# NUC1263AE register map
File version: 1.0
Registers are 32-bit, read-write, reset 0x0 unless marked. A register's access mark holds for its fields unless they carry their own. Offsets are from the block's base; [hi:lo] are bit positions; {n}, {i} and the like mark numbered series.

## SYS — SYS Register Map
Base 0x50000000
0x00 SYS_PDID ro reset not defined — Part Device Identification Number Register
  [31:0] PDID — Part Device Identification Number (Read Only). This register reflects device part number code. Software can read this register to identify which device is used.
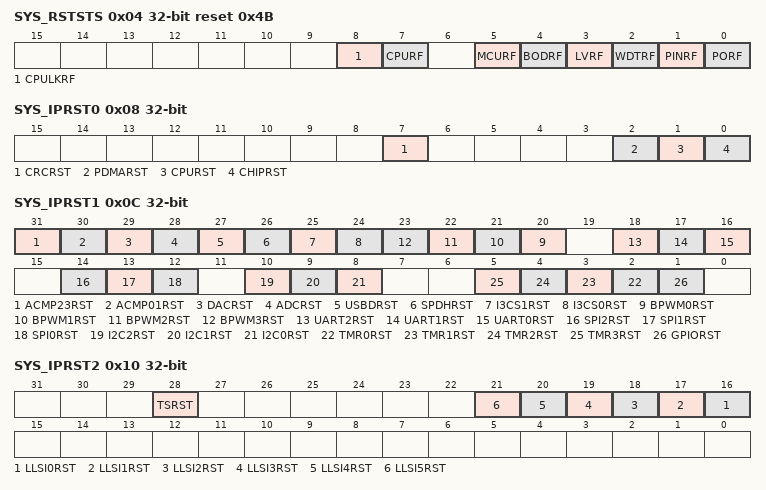
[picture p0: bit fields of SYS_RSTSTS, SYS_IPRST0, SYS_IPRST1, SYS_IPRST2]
0x04 SYS_RSTSTS reset 0x4B — System Reset Status Register
  [8] CPULKRF — CPU Lockup Reset Flag. The CPU lockup reset flag is set by hardware If Cortex-M23 lockup happened. Note 1: This bit can be cleared by software writing 1. Note 2: When CPU lockup happened under ICE is connected, This flag will set to 1 but chip will not reset.
    0=No reset from CPU lockup happened; 1=The Cortex-M23 lockup happened and chip is reset
  [7] CPURF — CPU Reset Flag. The CPU reset flag is set by hardware if software writes CPURST (SYS_IPRST0[1]) 1 to reset Cortex-M23 Core and Flash Memory Controller (FMC). Note: This bit can be cleared by software writing 1.
    0=No reset from CPU; 1=The Cortex-M23 Core and FMC are reset by software setting CPURST to 1
  [5] MCURF — MCU Reset Flag. The MCU reset flag is set by the 'Reset Signal' from the Cortex-M23 Core to indicate the previous reset source. Note: This bit can be cleared by software writing 1.
    0=No reset from Cortex-M23; 1=The Cortex-M23 had issued the reset signal to reset the system by writing 1 to the bit SYSRESETREQ(AIRCR[2], Application Interrupt and Reset Control Register, address = 0xE000ED0C) in system control registers of Cortex-M23 core
  [4] BODRF — BOD Reset Flag. The BOD reset flag is set by the 'Reset Signal' from the Brown-out Detector to indicate the previous reset source. Note: This bit can be cleared by software writing 1.
    0=No reset from BOD; 1=The BOD had issued the reset signal to reset the system
  [3] LVRF — LVR Reset Flag. The LVR reset flag is set by the 'Reset Signal' from the Low Voltage Reset Controller to indicate the previous reset source. Note: This bit can be cleared by software writing 1.
    0=No reset from LVR; 1=LVR controller had issued the reset signal to reset the system
  [2] WDTRF — WDT Reset Flag. The WDT reset flag is set by the 'Reset Signal' from the Watchdog Timer or Window Watchdog Timer to indicate the previous reset source. Note 1: This bit can be cleared by software writing 1. Note 2: Watchdog Timer register RSTF(WDT_CTL[2]) bit is set if the system has been reset by WDT time-out reset. Window Watchdog Timer register WWDTRF(WWDT_STATUS[1]) bit is set if the system has been reset by WWDT time-out reset.
    0=No reset from watchdog timer or window watchdog timer; 1=The watchdog timer or window watchdog timer had issued the reset signal to reset the system
  [1] PINRF — nRESET Pin Reset Flag. The nRESET pin reset flag is set by the 'Reset Signal' from the nRESET Pin to indicate the previous reset source. Note: This bit can be cleared by software writing 1.
    0=No reset from nRESET pin; 1=Pin nRESET had issued the reset signal to reset the system
  [0] PORF — POR Reset Flag. The POR reset flag is set by the 'Reset Signal' from the Power-on Reset (POR) Controller or bit CHIPRST (SYS_IPRST0[0]) to indicate the previous reset source. Note: This bit can be cleared by software writing 1.
    0=No reset from POR or CHIPRST; 1=Power-on Reset (POR) or CHIPRST had issued the reset signal to reset the system
0x08 SYS_IPRST0 — Peripheral Reset Control Register 0
  [7] CRCRST — CRC Calculation Controller Reset (Write Protect). Set this bit to 1 will generate a reset signal to the CRC calculation controller. User needs to set this bit to 0 to release from the reset state. Note: This bit is write protected. Refer to the SYS_REGLCTL register.
    0=CRC calculation controller normal operation; 1=CRC calculation controller reset
  [2] PDMARST — PDMA Controller Reset (Write Protect). Setting this bit to 1 will generate a reset signal to the PDMA. User needs to set this bit to 0 to release from reset state. Note: This bit is write protected. Refer to the SYS_REGLCTL register.
    0=PDMA controller normal operation; 1=PDMA controller reset
  [1] CPURST — Processor Core One-shot Reset (Write Protect). Setting this bit will only reset the processor core and Flash Memory Controller (FMC), and this bit will automatically return to 0 after the 2 clock cycles. Note: This bit is write protected. Refer to the SYS_REGLCTL register.
    0=Processor core normal operation; 1=Processor core one-shot reset
  [0] CHIPRST — Chip One-shot Reset (Write Protect). Setting this bit will reset the whole chip, including Processor core and all peripherals, and this bit will automatically return to 0 after the 2 clock cycles. The CHIPRST is same as the POR reset, all the chip controllers is reset and the chip setting from Flash are also reload. About the difference between CHIPRST and SYSRESETREQ(AIRCR[2]), please refer to section 6.2.2. Note: This bit is write protected. Refer to the SYS_REGLCTL register.
    0=Chip normal operation; 1=Chip one-shot reset
0x0C SYS_IPRST1 — Peripheral Reset Control Register 1
  [31] ACMP23RST — ACMP23 Controller Reset
    0=ACMP23 controller normal operation; 1=ACMP23 controller reset
  [30] ACMP01RST — ACMP01 Controller Reset
    0=ACMP01 controller normal operation; 1=ACMP01 controller reset
  [29] DACRST — DAC Controller Reset
    0=DAC controller normal operation; 1=DAC controller reset
  [28] ADCRST — ADC Controller Reset
    0=ADC controller normal operation; 1=ADC controller reset
  [27] USBDRST — USB Device Controller Reset
    0=USB device controller normal operation; 1=USB device controller reset
  [26] SPDHRST — SPD5 Hub Controller Reset
    0=SPD5 Hub controller normal operation; 1=SPD5 Hub controller reset
  [25] I3CS1RST — I3CS1 Controller Reset
    0=I3CS1 controller normal operation; 1=I3CS1 controller reset
  [24] I3CS0RST — I3CS0 Controller Reset
    0=I3CS0 controller normal operation; 1=I3CS0 controller reset
  [n+20] BPWM{n}RST (n=0..3) — BPWM{n} Controller Reset
    0=BPWM{n} controller normal operation; 1=BPWM{n} controller reset
  [18] UART2RST — UART2 Controller Reset
    0=UART2 controller normal operation; 1=UART2 controller reset
  [17] UART1RST — UART1 Controller Reset
    0=UART1 controller normal operation; 1=UART1 controller reset
  [16] UART0RST — UART0 Controller Reset
    0=UART0 controller normal operation; 1=UART0 controller reset
  [14] SPI2RST — SPI2 Controller Reset
    0=SPI2 controller normal operation; 1=SPI2 controller reset
  [13] SPI1RST — SPI1 Controller Reset
    0=SPI1 controller normal operation; 1=SPI1 controller reset
  [12] SPI0RST — SPI0 Controller Reset
    0=SPI0 controller normal operation; 1=SPI0 controller reset
  [10] I2C2RST — I2C2 Controller Reset
    0=I2C2 controller normal operation; 1=I2C2 controller reset
  [9] I2C1RST — I2C1 Controller Reset
    0=I2C1 controller normal operation; 1=I2C1 controller reset
  [8] I2C0RST — I2C0 Controller Reset
    0=I2C0 controller normal operation; 1=I2C0 controller reset
  [n+2] TMR{n}RST (n=0..3) — Timer{n} Controller Reset
    0=Timer{n} controller normal operation; 1=Timer{n} controller reset
  [1] GPIORST — GPIO Controller Reset
    0=GPIO controller normal operation; 1=GPIO controller reset
0x10 SYS_IPRST2 — Peripheral Reset Control Register 2
  [28] TSRST — TS Controller Reset
    0=Temperature Sensor controller normal operation; 1=Temperature Sensor controller reset
  [n+16] LLSI{n}RST (n=0..5) — LLSI{n} Controller Reset
    0=LED Lighting Strip Interface {n} controller normal operation; 1=LED Lighting Strip Interface {n} controller reset
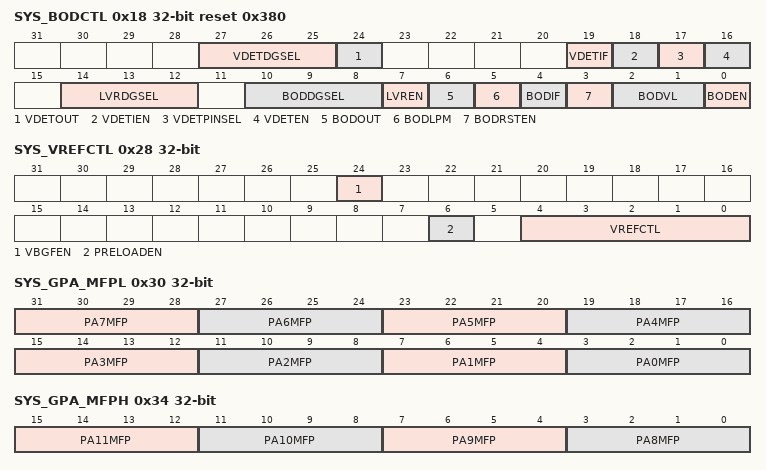
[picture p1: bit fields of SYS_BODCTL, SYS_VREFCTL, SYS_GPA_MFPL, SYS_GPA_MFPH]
0x18 SYS_BODCTL reset 0x380 (reset mask 0xFFFFFFF0) — Brown-out Detector Control Register
  [27:25] VDETDGSEL — Voltage Detector Output De-glitch Time Select (Write Protect). Note: These bits are write protected. Refer to the SYS_REGLCTL register.
    0=VDET output is sampled by VDET clock; 1=16 system clock (HCLK); 2=32 system clock (HCLK); 3=64 system clock (HCLK); 4=128 system clock (HCLK); 5=256 system clock (HCLK); 6=512 system clock (HCLK); 7=1024 system clock (HCLK)
  [24] VDETOUT — Voltage Detector Output Status. It means the detected voltage is lower than Band-gap. If the VDETEN is 0, VDET function is disabled. This bit always responds 0.
    0=VDET output status is 0; 1=VDET output status is 1
  [19] VDETIF — Voltage Detector Interrupt Flag. Note: This bit can be cleared by software writing 1.
    0=VDET does not detect any voltage draft at external pin down through or up through the voltage of Band-gap; 1=When VDET detects the external pin is dropped down through the voltage of Band-gap or the external pin is raised up through the voltage of Band-gap, this bit is set to 1 and the voltage detector interrupt is requested if voltage detector interrupt is enabled
  [18] VDETIEN — Voltage Detector Interrupt Enable Bit
    0=VDET interrupt Disabled; 1=VDET interrupt Enabled
  [17] VDETPINSEL — Voltage Detector External Input Voltage Pin Selection. Note 1: If VDET_P0 is selected, multi-function pin must be selected correctly in PB0MFP (SYS_GPB_MFPL[3:0]). Note 2: If VDET_P1 is selected, multi-function pin must be selected correctly in PB1MFP (SYS_GPB_MFPL[7:4]).
    0=The input voltage is from VDET_P0 (PB.0); 1=The input voltage is from VDET_P1 (PB.1)
  [16] VDETEN — Voltage Detector Enable Bit. Note 1: This function is still active in whole chip Power-down mode. Note 2: This function need use LIRC or LXT as VDET clock source, which is selected in VDETCKSEL (CLK_BODCLK[0]). Note 2: The input pin for VDET detect voltage is selectable by VDETPINSEL (SYS_BODCTL[17]).
    0=VDET detect external input voltage function Disabled; 1=VDET detect external input voltage function Enabled
  [14:12] LVRDGSEL — LVR Output De-glitch Time Select (Write Protect). Note: These bits are write protected. Refer to the SYS_REGLCTL register.
    0=Without de-glitch function; 1=4 system clock (HCLK); 2=8 system clock (HCLK); 3=16 system clock (HCLK); 4=32 system clock (HCLK); 5=64 system clock (HCLK); 6=128 system clock (HCLK); 7=256 system clock (HCLK)
  [10:8] BODDGSEL — Brown-out Detector Output De-glitch Time Select (Write Protect). Note: These bits are write protected. Refer to the SYS_REGLCTL register.
    0=BOD output is sampled by RC10K clock; 1=4 system clock (HCLK); 2=8 system clock (HCLK); 3=16 system clock (HCLK); 4=32 system clock (HCLK); 5=64 system clock (HCLK); 6=128 system clock (HCLK); 7=256 system clock (HCLK)
  [7] LVREN — Low Voltage Reset Enable Bit (Write Protect). The LVR function resets the chip when the input power voltage is lower than LVR circuit setting. LVR function is enabled by default. Note 1: After enabling the bit, the LVR function will be active with 200us delay for LVR output stable (default). Note 2: This bit is write protected. Refer to the SYS_REGLCTL register.
    0=Low Voltage Reset function Disabled; 1=Low Voltage Reset function Enabled
  [6] BODOUT — Brown-out Detector Output Status. It means the detected voltage is lower than BODVL setting. If the BODEN is 0, BOD function is disabled. This bit always responds 0.
    0=Brown-out Detector output status is 0; 1=Brown-out Detector output status is 1
  [5] BODLPM — Brown-out Detector Low Power Mode (Write Protect). Note 1: The BOD consumes about 100uA in normal mode, the low power mode can reduce the current to about 1/10 but slow the BOD response. Note 2: This bit is write protected. Refer to the SYS_REGLCTL register.
    0=BOD operated in normal mode (default); 1=BOD Low Power mode Enabled
  [4] BODIF — Brown-out Detector Interrupt Flag. Note: This bit can be cleared by software writing 1.
    0=Brown-out Detector does not detect any voltage draft at AVDD down through or up through the voltage of BODVL setting; 1=When Brown-out Detector detects the AVDD is dropped down through the voltage of BODVL setting or the AVDD is raised up through the voltage of BODVL setting, this bit is set to 1 and the brown-out interrupt is requested if brown-out interrupt is enabled
  [3] BODRSTEN — Brown-out Reset Enable Bit (Write Protect). The default value is set by Flash controller user configuration register CBORST(CONFIG0[20]) bit. Note 1: While the Brown-out Detector function is enabled (BODEN high) and BOD reset function is enabled (BODRSTEN high), BOD will assert a signal to reset chip when the detected voltage is lower than the threshold (BODOUT high). While the BOD function is enabled (BODEN high) and BOD interrupt function is enabled (BODRSTEN low), BOD will assert an interrupt if BODOUT is high. BOD interrupt will keep till to the BODEN set to 0. BOD interrupt can be blocked by disabling the NVIC BOD interrupt or disabling BOD function (set BODEN low). Note 2: This bit is write protected. Refer to the SYS_REGLCTL register.
    0=Brown-out 'INTERRUPT' function Enabled; 1=Brown-out 'RESET' function Enabled
  [2:1] BODVL — Brown-out Detector Threshold Voltage Selection (Write Protect). The default value is set by Flash controller user configuration register CBOV (CONFIG0 [22:21]). Note: These bits are write protected. Refer to the SYS_REGLCTL register.
    0=Brown-Out Detector threshold voltage is 2.2V; 1=Brown-Out Detector threshold voltage is 2.7V; 2=Brown-Out Detector threshold voltage is 3.7V; 3=Brown-Out Detector threshold voltage is 4.5V
  [0] BODEN — Brown-out Detector Enable Bit (Write Protect). The default value is set by Flash controller user configuration register CBODEN (CONFIG0 [23]). Note: This bit is write protected. Refer to the SYS_REGLCTL register.
    0=Brown-out Detector function Disabled; 1=Brown-out Detector function Enabled
0x1C SYS_IVSCTL — Internal Voltage Source Control Register
  [1] VBGUGEN — Band-gap VBG Unity Gain Buffer Enable Bit. This bit is used to enable/disable Band-gap VBG unity gain buffer function. Note: After this bit is set to 1, the value of VBG unity gain buffer output voltage can be obtained from ADC conversion result. Please refer to ADC function chapter for details.
    0=VBG unity gain buffer function Disabled (default); 1=VBG unity gain buffer function Enabled
0x24 SYS_PORCTL — Power-on Reset Controller Register
  [15:0] POROFF — Power-on Reset Enable Bit (Write Protect). When powered on, the POR circuit generates a reset signal to reset the whole chip function, but noise on the power may cause the POR active again. User can disable internal POR circuit to avoid unpredictable noise to cause chip reset by writing 0x5AA5 to this field. The POR function will be active again when this field is set to another value or chip is reset by other reset source, including: nRESET, Watchdog, LVR reset, BOD reset, ICE reset command and the software-chip reset function. Note: These bits are write protected. Refer to the SYS_REGLCTL register.
0x28 SYS_VREFCTL — VREF Control Register
  [24] VBGFEN — Chip Internal Voltage Band-gap Force Enable Bit (Write Protect)
    0=Chip internal voltage band-gap controlled by ADC/ACMP if source selected; 1=Chip internal voltage band-gap force enable
  [6] PRELOADEN — Pre-load Function Enable Bit (Write Protect). This bit should be enabled and keep during Tstable when VREFCTL(SYS_VREFCTL[4:0]) change setting(except set to 00000). Tstable depends on different situations has different requirement, please refer to Datasheet. Note : This bit is write protected. Refer to the SYS_REGLCTL register.
    0=VREF Pre-load function Disabled. (Default); 1=VREF Pre-load function Enabled
  [4:0] VREFCTL — VREF Control Bits (Write Protect). Note: These bits are write protected. Refer to the SYS_REGLCTL register.
    0=VREF is from external pin; 2=VREF is from internal reference voltage 2.048V; 6=VREF is from internal reference voltage 2.56V; 10=VREF is from internal reference voltage 3.072V; 14=VREF is from internal reference voltage 4.096V
0x30 SYS_GPA_MFPL — GPIOA Low Byte Multiple Function Control Register
  [31:28] PA7MFP — PA.7 Multi-function Pin Selection
    2=SPI1_CLK; 7=UART0_TXD; 8=I2C1_SCL; 11=BPWM3_CH4; 12=BPWM1_CH2; 13=ACMP0_WLAT; 14=TM2; 15=INT1
  [27:24] PA6MFP — PA.6 Multi-function Pin Selection
    2=SPI1_SS; 7=UART0_RXD; 8=I2C1_SDA; 11=BPWM3_CH5; 12=BPWM1_CH3; 13=ACMP1_WLAT; 14=TM3; 15=INT0
  [23:20] PA5MFP — PA.5 Multi-function Pin Selection
    2=SPI1_I2SMCLK; 4=SPI0_I2SMCLK; 5=SPI2_I2SMCLK; 6=I3CS0_SCL; 7=UART0_nCTS; 8=UART0_TXD; 9=I2C0_SCL; 12=BPWM0_CH5; 13=BPWM2_CH0; 15=DAC2_ST
  [19:16] PA4MFP — PA.4 Multi-function Pin Selection
    4=SPI0_I2SMCLK; 6=I3CS0_SDA; 7=UART0_nRTS; 8=UART0_RXD; 9=I2C0_SDA; 12=BPWM0_CH4; 13=BPWM2_CH1; 15=DAC3_ST
  [15:12] PA3MFP — PA.3 Multi-function Pin Selection
    2=SPI_SS_MUX; 4=SPI0_SS; 5=SPI2_SS; 6=I3CS1_SCL; 7=I2C0_SMBAL; 8=UART1_TXD; 9=I2C1_SCL; 10=LLSI4_OUT; 12=BPWM0_CH3; 13=BPWM2_CH2; 14=CLKO; 15=ACMP2_WLAT
  [11:8] PA2MFP — PA.2 Multi-function Pin Selection
    2=SPI_CLK_MUX; 4=SPI0_CLK; 5=SPI2_CLK; 6=I3CS1_SDA; 7=I2C0_SMBSUS; 8=UART1_RXD; 9=I2C1_SDA; 10=LLSI5_OUT; 12=BPWM0_CH2; 13=BPWM2_CH3; 15=ACMP3_WLAT
  [7:4] PA1MFP — PA.1 Multi-function Pin Selection
    2=SPI_MISO_MUX; 4=SPI0_MISO; 5=SPI2_MISO; 6=I3CS0_SCL; 7=UART0_TXD; 8=UART1_nCTS; 9=I2C2_SCL; 12=BPWM0_CH1; 13=BPWM2_CH4; 15=ACMP2_O
  [3:0] PA0MFP — PA.0 Multi-function Pin Selection
    2=SPI_MOSI_MUX; 4=SPI0_MOSI; 5=SPI2_MOSI; 6=I3CS0_SDA; 7=UART0_RXD; 8=UART1_nRTS; 9=I2C2_SDA; 12=BPWM0_CH0; 13=BPWM2_CH5; 14=ACMP3_O; 15=DAC0_ST
0x34 SYS_GPA_MFPH — GPIOA High Byte Multiple Function Control Register
  [15:12] PA11MFP — PA.11 Multi-function Pin Selection
    3=SPI1_MOSI; 4=SPI2_SS; 7=I2C2_SCL; 9=BPWM0_CH0; 13=TM0_EXT; 14=DAC1_ST
  [11:8] PA10MFP — PA.10 Multi-function Pin Selection
    3=SPI1_MISO; 4=SPI2_CLK; 7=I2C2_SDA; 9=BPWM0_CH1; 10=I2C1_SCL; 13=TM1_EXT; 14=DAC0_ST
  [7:4] PA9MFP — PA.9 Multi-function Pin Selection
    3=SPI1_CLK; 4=SPI2_MISO; 7=UART1_TXD; 9=BPWM0_CH2; 10=I2C1_SDA; 13=TM2_EXT; 14=DAC2_ST
  [3:0] PA8MFP — PA.8 Multi-function Pin Selection
    3=SPI1_SS; 4=SPI2_MOSI; 7=UART1_RXD; 9=BPWM0_CH3; 10=I2C0_SCL; 13=TM3_EXT; 14=DAC3_ST; 15=INT4
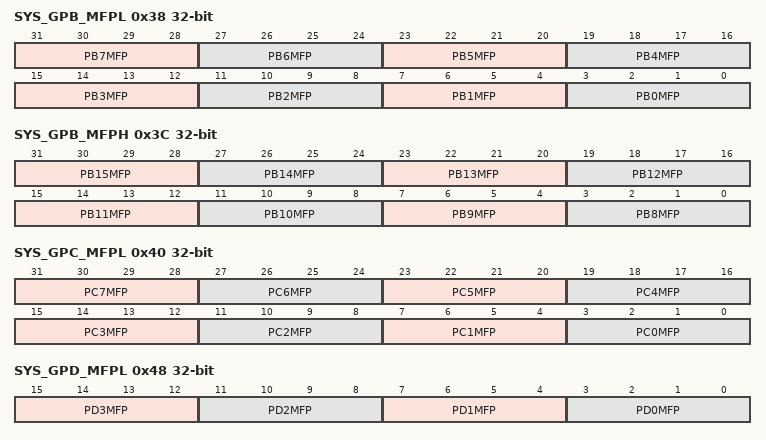
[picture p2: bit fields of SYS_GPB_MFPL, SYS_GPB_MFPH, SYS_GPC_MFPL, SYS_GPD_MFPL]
0x38 SYS_GPB_MFPL — GPIOB Low Byte Multiple Function Control Register
  [31:28] PB7MFP — PB.7 Multi-function Pin Selection
    1=ADC0_CH7, ACMP3_N; 6=UART1_TXD; 10=BPWM1_CH4; 12=BPWM3_CH4; 13=INT5; 15=ACMP0_O
  [27:24] PB6MFP — PB.6 Multi-function Pin Selection
    1=ADC0_CH6, ACMP2_N, ACMP3_P1; 6=UART1_RXD; 10=BPWM1_CH5; 12=BPWM3_CH5; 13=INT4; 15=ACMP1_O
  [23:20] PB5MFP — PB.5 Multi-function Pin Selection
    1=ADC0_CH5, ACMP1_N, ACMP2_P1, ACMP3_P0; 2=SPI1_MISO; 6=I2C0_SCL; 11=BPWM2_CH0; 12=LLSI4_OUT; 13=UART2_TXD; 14=TM0; 15=INT0
  [19:16] PB4MFP — PB.4 Multi-function Pin Selection
    1=ADC0_CH4, ACMP0_N, ACMP1_P1, ACMP2_P0; 2=SPI1_MOSI; 6=I2C0_SDA; 11=BPWM2_CH1; 12=LLSI5_OUT; 13=UART2_RXD; 14=TM1; 15=INT1
  [15:12] PB3MFP — PB.3 Multi-function Pin Selection
    1=ADC0_CH3, ACMP0_P1, ACMP1_P0; 2=SPI1_CLK; 4=I2C1_SCL; 6=UART1_TXD; 7=I2C2_SCL; 11=BPWM2_CH2; 14=TM2; 15=INT2
  [11:8] PB2MFP — PB.2 Multi-function Pin Selection
    1=ADC0_CH2, ACMP0_P0; 2=SPI1_SS; 4=I2C1_SDA; 6=UART1_RXD; 7=I2C2_SDA; 8=SPI0_I2SMCLK; 11=BPWM2_CH3; 14=TM3; 15=INT3
  [7:4] PB1MFP — PB.1 Multi-function Pin Selection
    1=ADC0_CH1, VDET_P1, SPDH_HSA; 2=SPI1_I2SMCLK; 7=UART2_TXD; 9=I2C1_SCL; 11=BPWM2_CH4; 12=BPWM3_CH4; 13=TM3_EXT
  [3:0] PB0MFP — PB.0 Multi-function Pin Selection
    1=ADC0_CH0, VDET_P0; 3=SPI0_SS; 4=SPI2_I2SMCLK; 7=UART2_RXD; 8=SPI0_I2SMCLK; 9=I2C1_SDA; 11=BPWM2_CH5; 12=BPWM3_CH5
0x3C SYS_GPB_MFPH — GPIOB High Byte Multiple Function Control Register
  [31:28] PB15MFP — PB.15 Multi-function Pin Selection
    1=ADC0_CH15, DAC3_OUT, ACMP2_P3, ACMP3_P3; 4=SPI0_SS; 6=UART0_nCTS; 8=I2C2_SMBAL; 10=LLSI0_OUT; 11=BPWM3_CH0; 13=TM0_EXT
  [27:24] PB14MFP — PB.14 Multi-function Pin Selection
    1=ADC0_CH14, DAC2_OUT, ACMP2_P2, ACMP3_P2; 4=SPI0_CLK; 6=UART0_nRTS; 8=I2C2_SMBSUS; 10=LLSI1_OUT; 11=BPWM3_CH1; 13=TM1_EXT; 14=CLKO
  [23:20] PB13MFP — PB.13 Multi-function Pin Selection
    1=ADC0_CH13, DAC1_OUT, ACMP0_P3, ACMP1_P3; 4=SPI0_MISO; 6=UART0_TXD; 8=I2C2_SCL; 10=LLSI2_OUT; 11=BPWM3_CH2; 13=TM2_EXT
  [19:16] PB12MFP — PB.12 Multi-function Pin Selection
    1=ADC0_CH12, DAC0_OUT, ACMP0_P2, ACMP1_P2; 4=SPI0_MOSI; 6=UART0_RXD; 8=I2C2_SDA; 10=LLSI3_OUT; 11=BPWM3_CH3; 13=TM3_EXT
  [15:12] PB11MFP — PB.11 Multi-function Pin Selection
    1=ADC0_CH11; 5=UART0_nCTS; 7=I2C1_SCL; 9=SPI0_I2SMCLK; 10=BPWM1_CH0
  [11:8] PB10MFP — PB.10 Multi-function Pin Selection
    1=ADC0_CH10; 5=UART0_nRTS; 7=I2C1_SDA; 10=BPWM1_CH1
  [7:4] PB9MFP — PB.9 Multi-function Pin Selection
    1=ADC0_CH9; 5=UART0_TXD; 6=UART1_nCTS; 7=I2C1_SMBAL; 9=I2C0_SCL; 10=BPWM1_CH2
  [3:0] PB8MFP — PB.8 Multi-function Pin Selection
    1=ADC0_CH8; 5=UART0_RXD; 6=UART1_nRTS; 7=I2C1_SMBSUS; 9=I2C0_SDA; 10=BPWM1_CH3
0x40 SYS_GPC_MFPL — GPIOC Low Byte Multiple Function Control Register
  [31:28] PC7MFP — PC.7 Multi-function Pin Selection
    4=SPI1_MISO; 7=UART0_nCTS; 8=I2C1_SMBAL; 11=BPWM3_CH2; 12=BPWM1_CH0; 14=TM0; 15=INT3
  [27:24] PC6MFP — PC.6 Multi-function Pin Selection
    4=SPI1_MOSI; 7=UART0_nRTS; 8=I2C1_SMBSUS; 11=BPWM3_CH3; 12=BPWM1_CH1; 14=TM1; 15=INT2
  [23:20] PC5MFP — PC.5 Multi-function Pin Selection
    8=UART2_TXD; 9=I2C1_SCL; 12=BPWM3_CH0; 15=LLSI0_OUT
  [19:16] PC4MFP — PC.4 Multi-function Pin Selection
    2=SPI1_I2SMCLK; 8=UART2_RXD; 9=I2C1_SDA; 12=BPWM3_CH1; 15=LLSI1_OUT
  [15:12] PC3MFP — PC.3 Multi-function Pin Selection
    2=SPI1_MISO; 7=I2C2_SMBAL; 8=UART2_nRTS; 9=I2C0_SMBAL; 10=I2C0_SCL; 12=BPWM3_CH2; 15=LLSI2_OUT
  [11:8] PC2MFP — PC.2 Multi-function Pin Selection
    2=SPI1_MOSI; 7=I2C2_SMBSUS; 8=UART2_nCTS; 9=I2C0_SMBSUS; 10=I2C0_SDA; 12=BPWM3_CH3; 15=LLSI3_OUT
  [7:4] PC1MFP — PC.1 Multi-function Pin Selection
    2=SPI1_CLK; 7=I2C1_SCL; 8=UART2_TXD; 9=I2C0_SCL; 11=ADC0_ST; 12=BPWM3_CH4; 13=BPWM2_CH1; 14=ACMP0_O
  [3:0] PC0MFP — PC.0 Multi-function Pin Selection
    2=SPI1_SS; 7=I2C1_SDA; 8=UART2_RXD; 9=I2C0_SDA; 12=BPWM3_CH5; 13=BPWM3_CH3; 14=ACMP1_O
0x44 SYS_GPC_MFPH — GPIOC High Byte Multiple Function Control Register
  [27:24] PC14MFP — PC14 Multi-function Pin Selection
    2=SPI1_MOSI; 4=SPI0_I2SMCLK; 13=TM1; 15=DAC1_ST
0x48 SYS_GPD_MFPL — GPIOD Low Byte Multiple Function Control Register
  [15:12] PD3MFP — PD.3 Multi-function Pin Selection
    4=SPI0_SS; 9=UART0_TXD
  [11:8] PD2MFP — PD.2 Multi-function Pin Selection
    4=SPI0_CLK; 9=UART0_RXD
  [7:4] PD1MFP — PD.1 Multi-function Pin Selection
    4=SPI0_MISO
  [3:0] PD0MFP — PD.0 Multi-function Pin Selection
    4=SPI0_MOSI; 14=TM2
0x4C SYS_GPD_MFPH — GPIOD High Byte Multiple Function Control Register
  [31:28] PD15MFP — PD.15 Multi-function Pin Selection
    12=BPWM2_CH5; 14=TM3; 15=INT1
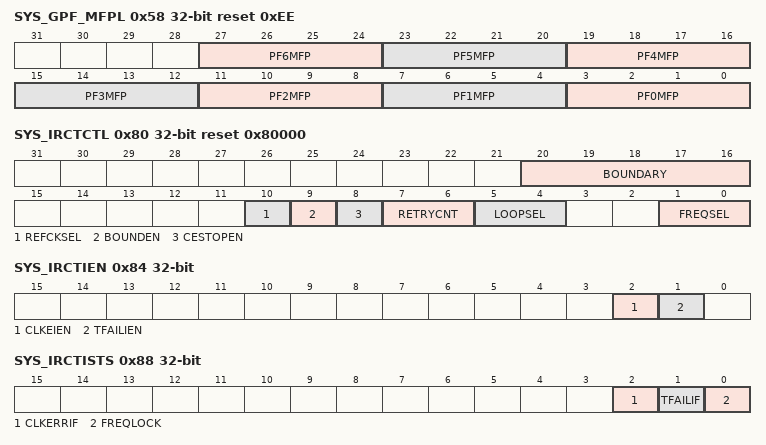
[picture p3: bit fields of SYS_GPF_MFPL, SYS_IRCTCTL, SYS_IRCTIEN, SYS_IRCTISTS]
0x58 SYS_GPF_MFPL reset 0xEE — GPIOF Low Byte Multiple Function Control Register
  [27:24] PF6MFP — PF.6 Multi-function Pin Selection
    5=SPI0_MOSI; 10=I2C0_SDA; 11=LLSI3_OUT; 12=BPWM2_CH4; 13=CLKO; 14=TM3; 15=INT5
  [23:20] PF5MFP — PF.5 Multi-function Pin Selection
    2=UART2_RXD; 3=SPI1_SS; 4=UART2_nCTS; 5=SPI0_CLK; 7=BPWM2_CH0; 8=BPWM0_CH4; 9=I2C0_SCL; 10=X32_IN; 11=ADC0_ST; 13=ACMP2_WLAT
  [19:16] PF4MFP — PF.4 Multi-function Pin Selection
    2=UART2_TXD; 4=UART2_nRTS; 5=SPI0_MISO; 7=BPWM2_CH1; 8=BPWM0_CH5; 9=I2C0_SDA; 10=X32_OUT; 11=BPWM2_CH5; 12=BPWM3_CH5; 13=ACMP3_WLAT
  [15:12] PF3MFP — PF.3 Multi-function Pin Selection
    3=UART0_TXD; 4=I2C0_SCL; 7=UART2_RXD; 9=BPWM0_CH3; 10=XT1_IN; 11=BPWM1_CH0; 13=ACMP2_O
  [11:8] PF2MFP — PF.2 Multi-function Pin Selection
    3=UART0_RXD; 4=I2C0_SDA; 7=UART1_RXD; 10=XT1_OUT; 11=BPWM1_CH1; 13=ACMP3_O; 15=INT4
  [7:4] PF1MFP — PF.1 Multi-function Pin Selection
    2=UART1_RXD; 3=I2C1_SDA; 4=UART0_RXD; 7=I2C2_SDA; 8=UART2_RXD; 9=I2C1_SMBSUS; 12=BPWM1_CH1; 13=ACMP1_O; 14=ICE_CLK
  [3:0] PF0MFP — PF.0 Multi-function Pin Selection
    2=UART1_TXD; 3=I2C1_SCL; 4=UART0_TXD; 7=I2C2_SCL; 8=UART2_TXD; 9=I2C1_SMBAL; 12=BPWM1_CH0; 13=ACMP0_O; 14=ICE_DAT
0x80 SYS_IRCTCTL reset 0x80000 — HIRC Trim Control Register
  [20:16] BOUNDARY — Boundary Selection. Fill the boundary range from 0x1 to 0x1F, 0x0 is reserved. Note: This field is effective only when the BOUNDEN(SYS_IRCTCTL[9]) is enabled.
  [10] REFCKSEL — Reference Clock Selection
    0=HIRC trim reference clock is from LXT (32.768 kHz); 1=HIRC trim reference clock is from USB synchronous mode packet
  [9] BOUNDEN — Boundary Enable Bit
    0=Boundary function Disabled; 1=Boundary function Enabled
  [8] CESTOPEN — Clock Error Stop Enable Bit
    0=The trim operation is keep going if clock is inaccurate; 1=The trim operation is stopped if clock is inaccurate
  [7:6] RETRYCNT — Trim Value Update Limitation Count. This field defines that how many times the auto trim circuit will try to update the HIRC trim value before the frequency of HIRC locked. Once the HIRC locked, the internal trim value update counter will be reset. If the trim value update counter reached this limitation value and frequency of HIRC is still not locked, the auto trim operation will be disabled and FREQSEL(SYS_IRCTCTL[1:0]) will be cleared to 00.
    0=Trim retry count limitation is 64 loops; 1=Trim retry count limitation is 128 loops; 2=Trim retry count limitation is 256 loops; 3=Trim retry count limitation is 512 loops
  [5:4] LOOPSEL — Trim Calculation Loop Selection. This field defines that trim value calculation is based on how many clocks of reference clock (32.768 kHz, LXT). Note: For example, if LOOPSEL is set as 00, auto trim circuit will calculate trim value based on the average frequency difference in 4 clocks of reference clock.
    0=Trim value calculation is based on average difference in 4 clocks of reference clock; 1=Trim value calculation is based on average difference in 8 clocks of reference clock; 2=Trim value calculation is based on average difference in 16 clocks of reference clock; 3=Trim value calculation is based on average difference in 32 clocks of reference clock
  [1:0] FREQSEL — Trim Frequency Selection. This field indicates the target frequency of internal high speed RC oscillator (HIRC) auto trim. During auto trim operation, if clock error detected with CESTOPEN(SYS_IRCTCTL[8]) is set to 1 or trim retry limitation count reached, this field will be cleared to 00 automatically.
    0=Disable HIRC auto trim function; 1=Enable HIRC auto trim function and trim HIRC to 48 MHz
0x84 SYS_IRCTIEN — HIRC Trim Interrupt Enable Register
  [2] CLKEIEN — HIRC Clock Error Interrupt Enable Bit. This bit controls if CPU would get an interrupt while HIRC clock is inaccurate during auto trim operation. If this bit is set to1, and CLKERRIF(SYS_IRCTSTS[2]) is set during auto trim operation, an interrupt will be triggered to notify the clock frequency is inaccurate.
    0=Disable CLKERRIF(SYS_IRCTSTS[2]) status to trigger an interrupt to CPU; 1=Enable CLKERRIF(SYS_IRCTSTS[2]) status to trigger an interrupt to CPU
  [1] TFAILIEN — HIRC Trim Failure Interrupt Enable Bit. This bit controls if an interrupt will be triggered while HIRC trim value update limitation count reached and HIRC frequency still not locked on target frequency set by FREQSEL(SYS_IRCTCTL[1:0]). If this bit is high and TFAILIF(SYS_IRCTSTS[1]) is set during auto trim operation, an interrupt will be triggered to notify that HIRC trim value update limitation count reached.
    0=Disable TFAILIF(SYS_IRCTSTS[1]) status to trigger an interrupt to CPU; 1=Enable TFAILIF(SYS_IRCTSTS[1]) status to trigger an interrupt to CPU
0x88 SYS_IRCTISTS — HIRC Trim Interrupt Status Register
  [2] CLKERRIF — Clock Error Interrupt Status. When the frequency of 32.768 kHz external low speed crystal oscillator (LXT) or 48 MHz internal high speed RC oscillator (HIRC) is shift larger to unreasonable value, this bit will be set and indicate that clock frequency is inaccurate. Once this bit is set to 1, the auto trim operation stopped and FREQSEL(SYS_IRCTCTL[1:0]) will be cleared to 00 by hardware automatically if CESTOPEN(SYS_IRCTCTL[8]) is set to 1. If this bit is set and CLKEIEN(SYS_IRCTIEN[2]) is high, an interrupt will be triggered to notify the clock frequency is inaccurate. Write 1 to clear this to 0.
    0=Clock frequency is accurate; 1=Clock frequency is inaccurate
  [1] TFAILIF — Trim Failure Interrupt Status. This bit indicates that HIRC trim value update limitation count reached and the HIRC clock frequency is still not locked. Once this bit is set, the auto trim operation stopped and FREQSEL(SYS_IRCTCTL[1:0]) will be cleared to 00 by hardware automatically. If this bit is set and TFAILIEN(SYS_IRCTIEN[1]) is high, an interrupt will be triggered to notify that HIRC trim value update limitation count reached. Write 1 to clear this to 0.
    0=Trim value update limitation count not reached; 1=Trim value update limitation count reached and HIRC frequency still not locked
  [0] FREQLOCK — HIRC Frequency Lock Status. This bit indicates the HIRC frequency is locked. This is a status bit and does not trigger any interrupt.
    0=The internal high-speed RC oscillator frequency is not locked at 48 MHz yet; 1=The internal high-speed RC oscillator frequency locked at 48 MHz
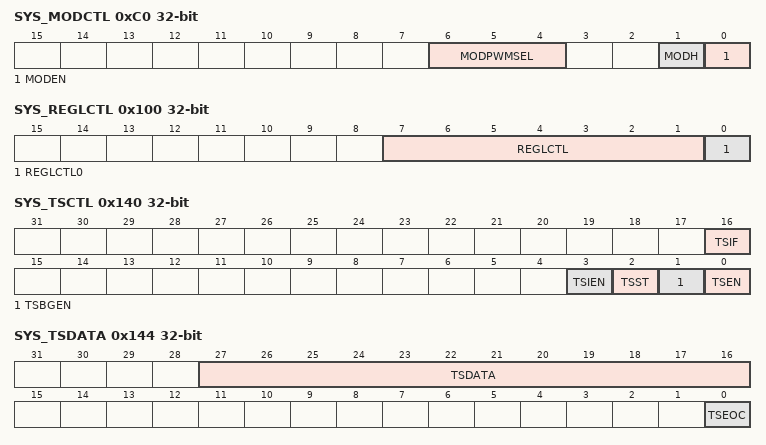
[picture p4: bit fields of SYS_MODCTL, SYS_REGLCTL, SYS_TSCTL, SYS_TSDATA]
0xC0 SYS_MODCTL — Modulation Control Register
  [6:4] MODPWMSEL — BPWM0 Channel Select for Modulation. Select the BPWM0 channel to modulate with the UART1_TXD. Note: These bits are valid while MODEN (SYS_MODCTL[0]) is set to 1.
    {v}=BPWM0 channel {v} modulate with UART1_TXD (v=0..3)
  [1] MODH — Modulation at Data High. Select modulation pulse (BPWM) at UART1_TXD high or low.
    0=Modulation pulse at UART1_TXD low; 1=Modulation pulse at UART1_TXD high
  [0] MODEN — Modulation Function Enable Bit. This bit enables modulation function by modulating with BPWM channel output and UART1_TXD.
    0=Modulation Function Disabled; 1=Modulation Function Enabled
0x100 SYS_REGLCTL — Register Lock Control Register
  [7:1] REGLCTL — Register Lock Control Code (Write Only). Some registers have write-protection function. Writing these registers have to disable the protected function by writing the sequence value '59h', '16h', '88h' to this field. After this sequence is completed, the REGLCTL bit will be set to 1 and write-protection registers can be normal write.
  [0] REGLCTL0 — Register Lock Control Disable Index (Read Only). The Protected registers are: SYS_IPRST0: address 0x5000_0008. SYS_BODCTL: address 0x5000_0018. SYS_PORCTL: address 0x5000_0024. SYS_VREFCTL: address 0x5000_0028. CLK_PWRCTL: address 0x5000_0200. CLK_APBCLK0: address 0x5000_0208. CLK_CLKSEL0: address 0x5000_0210. CLK_CLKSEL1: address 0x5000_0214. CLK_CLKSEL3: address 0x5000_0234. CLK_CLKDSTS: address 0x5000_0274. FMC_ISPCTL: address 0x5000_C000 (Flash ISP Control register). FMC_ISPTRG: address 0x5000_C010 (ISP Trigger Control register). FMC_FTCTL: address 0x5000_C018. FMC_ISPSTS: address 0x5000_C040. WDT_CTL: address 0x4000_4000. BPWM0_CTL0: address 0x4004_0000. BPWM1_CTL0: address 0x4014_0000. BPWM2_CTL0: address 0x4004_4000. BPWM3_CTL0: address 0x4014_4000. TIMER0_CTL: address 0x4001_0000. TIMER1_CTL: address 0x4001_0020. TIMER2_CTL: address 0x4011_0000. TIMER3_CTL: address 0x4011_0020
    0=Write-protection Enabled for writing protected registers. Any write to the protected register is ignored; 1=Write-protection Disabled for writing protected registers
0x140 SYS_TSCTL — Temperature Sensor Control Register
  [16] TSIF — Temperature Sensor Interrupt Flag. This bit indicates the end of temperature sensor conversion. This bit will be set automatically when temperature sensor conversion is finished. Note: Write 1 to clear this to 0.
    0=Tempertaure Sensor conversion not finished; 1=Tempertaure Sensor conversion finished
  [3] TSIEN — Temperature Sensor Interrupt Enable Bit. If this bit is set to 1, temperature sensor interrupt is requested when TSIF (SYS_TSCTL[16]) is set.
    0=Temperature Sensor finish interrupt Disabled. (Default); 1=Temperature Sensor finish interrupt Enabled
  [2] TSST — Temperature Sensor Conversion Start. Note 1: User needs to set TSEN first, and wait for at least 200us to start temperature sensor conversion. Note 2: This bit will be cleared to 0 by hardware automatically when temperature sensor conversion is finished.
    0=Conversion stoped or finished. (Default); 1=Conversion starts
  [1] TSBGEN — Temperature Sensor Band-gap Enable Bit. If this bit is set to 1, Temperature sensor band-gap will be enabled and Temperature sensor will supply current source to DAC and Internal Voltage Reference. Note: After TSBGEN is set, users should wait 200us stable time to enable DACEN(DACx_CTL[0]) or VREFEN (SYS_VREFCTL[0]).
    0=Temperature Sensor Band-gap function Disabled. (Default); 1=Temperature Sensor Band-gap function Enabled
  [0] TSEN — Temperature Sensor Enable Bit. Note: TSEN should be enabled only when TSBGEN is enabled.
    0=Temperature Sensor function Disabled. (Default); 1=Temperature Sensor function Enabled
0x144 SYS_TSDATA — Temperature Sensor Data Register
  [27:16] TSDATA ro — Temperature Sensor Conversion Data Bits (Read Only). This field present the conversion result of Temperature Sensor, ranges from -40C to 105C. Note: Negative temperature is represented by 2's complement format, and per LSB difference is equivalent to 0.0625C
  [0] TSEOC — Temperature Sensor Conversion Finish Flag. This bit indicates the end of temperature sensor conversion. Note: Write 1 to clear this bit to 0.
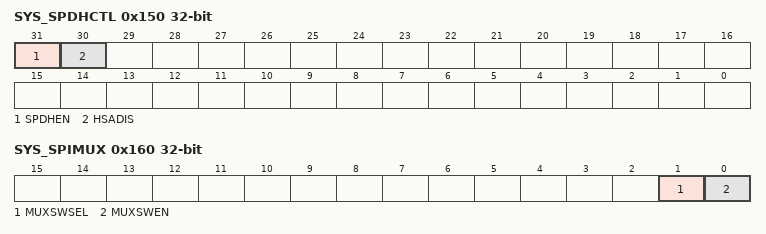
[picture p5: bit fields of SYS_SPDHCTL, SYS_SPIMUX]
0x150 SYS_SPDHCTL (reset mask 0xFFFFF00) — SPD5 Hub Control Register
  [31] SPDHEN — SPD5 Hub Controller Enable Bit (Write Protect). This bit is used to enable the whole SPD5 Hub controller function. When SPD5 Hub Function is enabled, I3CS0 and I3CS1 are for DDR5 platform purpose only. When SPD5 Hub Function is disabled, I3CS0 and I3CS1 are general purpose I3C slave.
    0=SPD5 Hub Function disabled; 1=SPD5 Hub Function enabled
  [30] HSADIS — HSA Resistor Disable Bit (Write Protect). This bit is used to disable SPD5 Hub HSA resistor.
    0=SPD5 Hub HSA Resistor enabled; 1=SPD5 Hub HSA Resistor disabled (default)
0x160 SYS_SPIMUX — SPI Mux Function Control Register
  [1] MUXSWSEL — SPI Mux Software Selection Mode Selection Bit. This bit is used to select which SPI master's signals are going to pass through the SPI mux in software selection mode.
    0=Choose external SPI master (default); 1=Choose internal SPI master
  [0] MUXSWEN — SPI Mux Software Selection Mode Enable Bit. This bit is used to enable/disable SPI Mux software selection mode function. Note: By default, SPI mux is controlled by SPI_SS_MUX.
    0=SPI Mux software selection mode Disabled (default); 1=SPI Mux software selection mode Enabled
